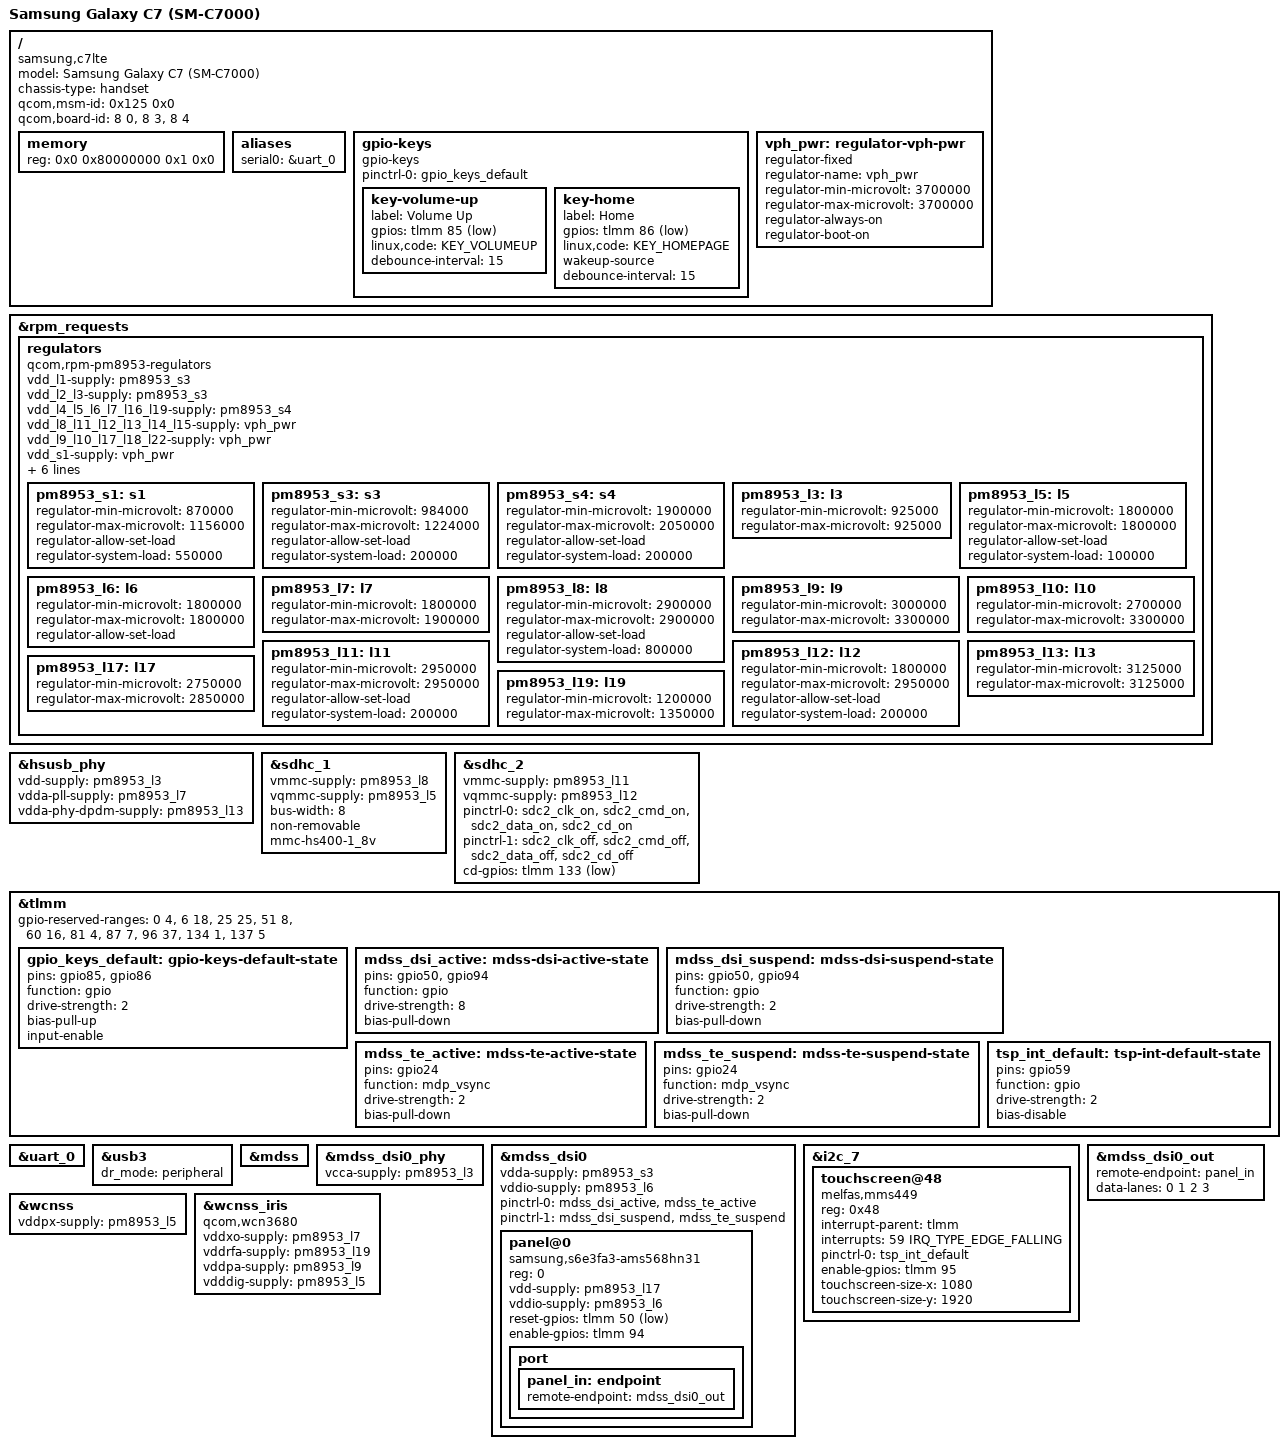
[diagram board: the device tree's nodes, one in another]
// SPDX-License-Identifier: BSD-3-Clause
/*
 * Samsung Galaxy C7 (SM-C7000, "c7lte") - mainline MSM8953 device tree
 *
 * Board data derived from the Samsung downstream tree:
 *   arch/arm64/boot/dts/samsung/msm8953/msm8953-sec-c7lte_chn-r04.dts
 *   arch/arm64/boot/dts/samsung/msm8953/msm8953-sec-c7lte_chn-pinctrl-r02.dtsi
 * and from mainline msm8953-xiaomi-vince.dts.
 *
 * STATUS: bring-up. Storage (eMMC/SD), UART, USB, display, touch, keys and
 * the WCNSS WiFi block are wired up here.  Sound, sensors, camera and NFC
 * are still missing (see docs/04-roadmap.md).
 *
 * Known C7 wiring (kept here as documentation, do not guess when adding
 * the drivers):
 *   panel   Samsung S6E3FA3 AMS568HN31, 1080x1920 command mode DSI,
 *           TE gpio24, reset gpio50, enable gpio94
 *   touch   Melfas MMS449 (mms_ts) at 0x48 on i2c_7 (BLSP2 QUP3),
 *           irq gpio59, vdd_en gpio95
 *   keys    volume-up gpio85, home gpio86, power via PM8953 PON
 *   sdc2    card detect gpio133 (active low)
 */

/dts-v1/;

#include "msm8953.dtsi"
#include "pm8953.dtsi"
#include <dt-bindings/gpio/gpio.h>
#include <dt-bindings/input/linux-event-codes.h>

/ {
	model = "Samsung Galaxy C7 (SM-C7000)";
	compatible = "samsung,c7lte", "qcom,msm8953";
	chassis-type = "handset";

	/* Same identification the Samsung downstream DTB uses. The
	 * bootloader picks this FDT out of the QCDT table in boot.img and
	 * patches /memory below with the real RAM size.
	 *
	 * Both properties are mandatory: dtbTool turns every
	 * (qcom,msm-id, qcom,board-id) pair into one QCDT entry, and a dtb
	 * without qcom,msm-id is dropped with "No valid dtbs found".
	 * 0x125 is QCOM_ID_MSM8953. board-id is <variant subtype>, and the
	 * three boot paths disagree about the subtype:
	 *   8/0  what lk2nd itself derives from SMEM (variant 8, subtype 0);
	 *        lk2nd logs "Unable to find suitable device tree for device
	 *        (293/0x00010001/0x00010008/0)" without this entry
	 *   8/3  what the lk2nd image that boots on this phone advertises
	 *   8/4  what the Samsung downstream C7 tree uses
	 * Ship all three so both the ABL and the lk2nd path can pick it. */
	qcom,msm-id = <0x125 0x0>;
	qcom,board-id = <8 0>, <8 3>, <8 4>;

	/* msm8953.dtsi names it memory@10000000, but both Samsung's ABL and
	 * LK patch the node at the literal path "/memory". Without the
	 * rename the bootloader cannot fill in the RAM size and the kernel
	 * comes up with zero memory. */
	/delete-node/ memory@10000000;

	memory {
		device_type = "memory";
		reg = <0x0 0x80000000 0x1 0x0>; /* 4 GiB fallback, ABL overrides */
	};

	aliases {
		serial0 = &uart_0;
	};

	gpio-keys {
		compatible = "gpio-keys";
		/* The initramfs only calls check_keys() from wait_partition(),
		 * i.e. while a boot/root partition is still missing.  With a
		 * flashed userdata partition that never happens, so the keys
		 * are safe to enable now that gpio_keys requests the lines as
		 * inputs (GPIOD_IN) instead of trusting the bootloader. */
		status = "okay";
		pinctrl-names = "default";
		pinctrl-0 = <&gpio_keys_default>;

		key-volume-up {
			label = "Volume Up";
			gpios = <&tlmm 85 GPIO_ACTIVE_LOW>;
			linux,code = <KEY_VOLUMEUP>;
			debounce-interval = <15>;
		};

		key-home {
			label = "Home";
			gpios = <&tlmm 86 GPIO_ACTIVE_LOW>;
			linux,code = <KEY_HOMEPAGE>;
			wakeup-source;
			debounce-interval = <15>;
		};
	};

	vph_pwr: regulator-vph-pwr {
		compatible = "regulator-fixed";
		regulator-name = "vph_pwr";
		regulator-min-microvolt = <3700000>;
		regulator-max-microvolt = <3700000>;
		regulator-always-on;
		regulator-boot-on;
	};
};

/*
 * PM8953 rails used by the C7 (from the downstream regulator table):
 *   l5  1.8V   eMMC I/O
 *   l6  1.8V   sensors / codec
 *   l8  2.9V   eMMC
 *   l10 2.7-3.3V  camera / misc
 *   l11 2.95V  SD card
 *   l12 1.8-2.95V  SD card I/O
 *   l17 2.75-2.85V  NFC / misc
 */
&rpm_requests {
	regulators {
		compatible = "qcom,rpm-pm8953-regulators";

		vdd_l1-supply = <&pm8953_s3>;
		vdd_l2_l3-supply = <&pm8953_s3>;
		vdd_l4_l5_l6_l7_l16_l19-supply = <&pm8953_s4>;
		vdd_l8_l11_l12_l13_l14_l15-supply = <&vph_pwr>;
		vdd_l9_l10_l17_l18_l22-supply = <&vph_pwr>;
		vdd_s1-supply = <&vph_pwr>;
		vdd_s2-supply = <&vph_pwr>;
		vdd_s3-supply = <&vph_pwr>;
		vdd_s4-supply = <&vph_pwr>;
		vdd_s5-supply = <&vph_pwr>;
		vdd_s6-supply = <&vph_pwr>;
		vdd_s7-supply = <&vph_pwr>;

		pm8953_s1: s1 {
			regulator-min-microvolt = <870000>;
			regulator-max-microvolt = <1156000>;
			regulator-allow-set-load;
			regulator-system-load = <550000>;
		};

		pm8953_s3: s3 {
			regulator-min-microvolt = <984000>;
			regulator-max-microvolt = <1224000>;
			regulator-allow-set-load;
			regulator-system-load = <200000>;
		};

		pm8953_s4: s4 {
			regulator-min-microvolt = <1900000>;
			regulator-max-microvolt = <2050000>;
			regulator-allow-set-load;
			regulator-system-load = <200000>;
		};

		pm8953_l3: l3 {
			regulator-min-microvolt = <925000>;
			regulator-max-microvolt = <925000>;
		};

		pm8953_l5: l5 {
			regulator-min-microvolt = <1800000>;
			regulator-max-microvolt = <1800000>;
			regulator-allow-set-load;
			regulator-system-load = <100000>;
		};

		pm8953_l6: l6 {
			regulator-min-microvolt = <1800000>;
			regulator-max-microvolt = <1800000>;
			regulator-allow-set-load;
		};

		pm8953_l7: l7 {
			regulator-min-microvolt = <1800000>;
			regulator-max-microvolt = <1900000>;
		};

		pm8953_l8: l8 {
			regulator-min-microvolt = <2900000>;
			regulator-max-microvolt = <2900000>;
			regulator-allow-set-load;
			regulator-system-load = <800000>;
		};

		/* iris vddpa: downstream runs this rail at 3.0 V and lets the
		 * WCN3680 driver bump it to 3.3 V. */
		pm8953_l9: l9 {
			regulator-min-microvolt = <3000000>;
			regulator-max-microvolt = <3300000>;
		};

		pm8953_l10: l10 {
			regulator-min-microvolt = <2700000>;
			regulator-max-microvolt = <3300000>;
		};

		pm8953_l11: l11 {
			regulator-min-microvolt = <2950000>;
			regulator-max-microvolt = <2950000>;
			regulator-allow-set-load;
			regulator-system-load = <200000>;
		};

		pm8953_l12: l12 {
			regulator-min-microvolt = <1800000>;
			regulator-max-microvolt = <2950000>;
			regulator-allow-set-load;
			regulator-system-load = <200000>;
		};

		pm8953_l13: l13 {
			regulator-min-microvolt = <3125000>;
			regulator-max-microvolt = <3125000>;
		};

		pm8953_l17: l17 {
			regulator-min-microvolt = <2750000>;
			regulator-max-microvolt = <2850000>;
		};

		/* iris vddrfa: downstream init 1.2 V, wcn3680 asks for 1.3 V. */
		pm8953_l19: l19 {
			regulator-min-microvolt = <1200000>;
			regulator-max-microvolt = <1350000>;
		};
	};
};

&hsusb_phy {
	vdd-supply = <&pm8953_l3>;
	vdda-pll-supply = <&pm8953_l7>;
	vdda-phy-dpdm-supply = <&pm8953_l13>;
	status = "okay";
};

&sdhc_1 {
	vmmc-supply = <&pm8953_l8>;
	vqmmc-supply = <&pm8953_l5>;

	bus-width = <8>;
	non-removable;
	mmc-hs400-1_8v;

	status = "okay";
};

&sdhc_2 {
	vmmc-supply = <&pm8953_l11>;
	vqmmc-supply = <&pm8953_l12>;

	pinctrl-names = "default", "sleep";
	pinctrl-0 = <&sdc2_clk_on &sdc2_cmd_on &sdc2_data_on &sdc2_cd_on>;
	pinctrl-1 = <&sdc2_clk_off &sdc2_cmd_off &sdc2_data_off &sdc2_cd_off>;

	cd-gpios = <&tlmm 133 GPIO_ACTIVE_LOW>;
	status = "okay";
};

&tlmm {
	/*
	 * Experiment: none of these lines may be read during gpiochip
	 * registration. Reading one of them aborts the bus
	 * ("synchronous external abort" in msm_gpio_get_direction), and
	 * gpiolib reads the direction of every valid line before
	 * of_gpiochip_add() has parsed any per-line exceptions.
	 *
	 * Reserving every line made the kernel get past pinctrl probe (the
	 * earlier all-valid attempt died in msm_gpio_get_direction), so the
	 * abort is caused by one of the extra pages this bootloader locks.
	 * Start from the usual msm8953 set and add the tail pages that
	 * Qualcomm boards with a Samsung ABL are known to protect.
	 */
	/* Only the pins our drivers actually use stay enabled: 4/5 UART, 24/50/94 panel,
	 * 59/95 touch, 76-80 WCNSS (wcss_wlan0/wlan1/wlan2/wlan), 85/86 keys, 133 SD
	 * card detect, 135/136 i2c7.  Reading the control register of any other pin
	 * raises a synchronous external abort on this bootloader (verified for pin
	 * 0 and pin 12), so the rest is reserved.
	 */
	gpio-reserved-ranges = <0 4>, <6 18>, <25 25>, <51 8>,
			       <60 16>, <81 4>, <87 7>, <96 37>, <134 1>, <137 5>;

	gpio_keys_default: gpio-keys-default-state {
		pins = "gpio85", "gpio86";
		function = "gpio";
		drive-strength = <2>;
		bias-pull-up;
		input-enable;
	};

	/*
	 * Panel reset (gpio50) and enable (gpio94).  The downstream Samsung
	 * pinctrl file only muxes them as plain GPIOs with a pull-down; the
	 * levels are driven by the panel driver, not by pinctrl.
	 */
	mdss_dsi_active: mdss-dsi-active-state {
		pins = "gpio50", "gpio94";
		function = "gpio";
		drive-strength = <8>;
		bias-pull-down;
	};

	mdss_dsi_suspend: mdss-dsi-suspend-state {
		pins = "gpio50", "gpio94";
		function = "gpio";
		drive-strength = <2>;
		bias-pull-down;
	};

	/* TE pin (gpio24) is not used by the mainline driver: MDP5 command
	 * mode drives its tear check from the internal vsync clock.  Keep the
	 * mux documented so a future DSI TE implementation can use it. */
	mdss_te_active: mdss-te-active-state {
		pins = "gpio24";
		function = "mdp_vsync";
		drive-strength = <2>;
		bias-pull-down;
	};

	mdss_te_suspend: mdss-te-suspend-state {
		pins = "gpio24";
		function = "mdp_vsync";
		drive-strength = <2>;
		bias-pull-down;
	};

	/* MMS449 interrupt line, driven open drain by the controller. */
	tsp_int_default: tsp-int-default-state {
		pins = "gpio59";
		function = "gpio";
		drive-strength = <2>;
		bias-disable;
	};
};

&uart_0 {
	/*
	 * No pinctrl state: the pin mux is already set by the bootloader for
	 * the console UART, and requesting it here makes msm_serial defer
	 * behind pinctrl probing. That delay is real: with the display nodes
	 * enabled, the UART only registered at 0.839 s while /init started at
	 * 0.787 s, so the kernel printed "unable to open an initial console"
	 * and the initramfs had to run without one.
	 */
	/delete-property/ pinctrl-names;
	/delete-property/ pinctrl-0;
	status = "okay";
};

/*
 * Kernel 7.x folded the old "usb3_dwc3" child node into the controller node
 * itself, so the role switch and dr_mode are properties of &usb3 now.
 */
&usb3 {
	/delete-property/ usb-role-switch;
	dr_mode = "peripheral";
	status = "okay";
};

/*
 * Display: Samsung S6E3FA3 AMS568HN31, 1080x1920 command mode AMOLED.
 *
 * The panel is a command-mode DSI panel: the host pushes frames into the
 * panel's frame memory and the panel refreshes itself, so no TE pin is
 * wired up here.  Supplies follow the downstream Samsung device tree:
 * DSI controller vdda = pm8953_s3, vddio = pm8953_l6, PHY vcca = pm8953_l3,
 * panel vdd = pm8953_l17, panel vddio = pm8953_l6.
 */
&mdss {
	status = "okay";
};

&mdss_dsi0_phy {
	vcca-supply = <&pm8953_l3>;
	status = "okay";
};

&mdss_dsi0 {
	vdda-supply = <&pm8953_s3>;
	vddio-supply = <&pm8953_l6>;
	status = "okay";

	/* dsi_host.c selects these with pinctrl_pm_select_default_state()
	 * and _sleep_state() around host power on/off. */
	pinctrl-names = "default", "sleep";
	pinctrl-0 = <&mdss_dsi_active &mdss_te_active>;
	pinctrl-1 = <&mdss_dsi_suspend &mdss_te_suspend>;

	panel@0 {
		compatible = "samsung,s6e3fa3-ams568hn31";
		reg = <0>;

		vdd-supply = <&pm8953_l17>;
		vddio-supply = <&pm8953_l6>;

		reset-gpios = <&tlmm 50 GPIO_ACTIVE_LOW>;
		enable-gpios = <&tlmm 94 GPIO_ACTIVE_HIGH>;

		port {
			panel_in: endpoint {
				remote-endpoint = <&mdss_dsi0_out>;
			};
		};
	};
};

/*
 * Touch: Melfas MMS449 on BLSP2 QUP3 (i2c_7) at 0x48.  The controller is
 * powered from a switch on gpio95 (vdd_en, active high) and raises its
 * interrupt line (gpio59) when an event packet is queued.  It has no reset
 * line and needs no firmware download.
 */
&i2c_7 {
	status = "okay";

	touchscreen@48 {
		compatible = "melfas,mms449";
		reg = <0x48>;

		interrupt-parent = <&tlmm>;
		interrupts = <59 IRQ_TYPE_EDGE_FALLING>;

		pinctrl-names = "default";
		pinctrl-0 = <&tsp_int_default>;

		enable-gpios = <&tlmm 95 GPIO_ACTIVE_HIGH>;

		touchscreen-size-x = <1080>;
		touchscreen-size-y = <1920>;
	};
};

/*
 * Link the DSI output to the panel and tell the host how many lanes are
 * routed.  The mainline SoC dtsi leaves this endpoint empty; dsi_host.c
 * reads "data-lanes" from it (of_graph_get_endpoint_by_regs(np, 1, -1)).
 */
&mdss_dsi0_out {
	remote-endpoint = <&panel_in>;
	data-lanes = <0 1 2 3>;
};

/*
 * WiFi: Qualcomm WCNSS (Pronto v3) + an external 802.11ac companion.  The
 * C7 is a Snapdragon 625 device with 11ac, so the iris is a WCN3680.
 * The radio firmware (wcnss.mdt, wcnss.b* and WCNSS_qcom_wlan_nv.bin) comes
 * from the phone's apnhlos partition (msm-firmware-loader mounts it) plus
 * the NV blob shipped by device-samsung-c7lte.
 *
 * The WCNSS remoteproc is not auto-booted by the kernel, so userspace has to
 * write "start" to /sys/class/remoteproc/remoteprocN/state before the wcn36xx
 * driver can open its SMD channels; see /etc/local.d/10-wcnss.start.
 */
&wcnss {
	/* pronto-v3 rail; the cx/mx core rails come from the RPM power
	 * domains already described in msm8953.dtsi. */
	vddpx-supply = <&pm8953_l5>;
	status = "okay";
};

&wcnss_iris {
	compatible = "qcom,wcn3680";

	/* qcom_wcnss_iris requests all four rails unconditionally
	 * (drivers/remoteproc/qcom_wcnss_iris.c, wcn3680_data). */
	vddxo-supply = <&pm8953_l7>;
	vddrfa-supply = <&pm8953_l19>;
	vddpa-supply = <&pm8953_l9>;
	vdddig-supply = <&pm8953_l5>;
};
